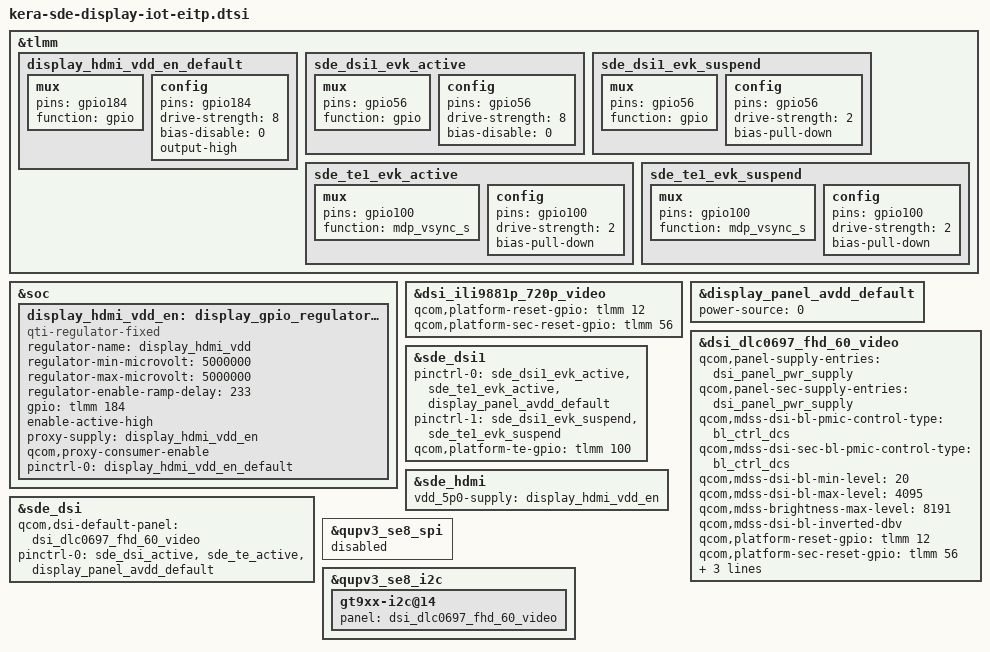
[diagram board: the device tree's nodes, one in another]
// SPDX-License-Identifier: BSD-3-Clause
/*
 * Copyright (c) Qualcomm Technologies, Inc. and/or its subsidiaries.
 */

#include "kera-sde-display-iot-cdp.dtsi"

&tlmm {
	display_hdmi_vdd_en_default: display_hdmi_vdd_en_default {
		mux {
			pins = "gpio184";
			function = "gpio";
		};

		config {
			pins = "gpio184";
			drive-strength = <8>;
			bias-disable = <0>;
			output-high;
		};
	};

	sde_dsi1_evk_active: sde_dsi1_evk_active {
		mux {
			pins = "gpio56";
			function = "gpio";
		};

		config {
			pins = "gpio56";
			drive-strength = <8>;   /* 8 mA */
			bias-disable = <0>;   /* no pull */
		};
	};

	sde_dsi1_evk_suspend: sde_dsi1_evk_suspend {
		mux {
			pins = "gpio56";
			function = "gpio";
		};

		config {
			pins = "gpio56";
			drive-strength = <2>;   /* 2 mA */
			bias-pull-down;         /* PULL DOWN */
		};
	};

	sde_te1_evk_active: sde_te1_evk_active {
		mux {
			pins = "gpio100";
			function = "mdp_vsync_s";
		};

		config {
			pins = "gpio100";
			drive-strength = <2>;   /* 2 mA */
			bias-pull-down;         /* PULL DOWN */
		};
	};

	sde_te1_evk_suspend: sde_te1_evk_suspend {
		mux {
			pins = "gpio100";
			function = "mdp_vsync_s";
		};

		config {
			pins = "gpio100";
			drive-strength = <2>;   /* 2 mA */
			bias-pull-down;         /* PULL DOWN */
		};
	};
};

&soc {
	display_hdmi_vdd_en: display_gpio_regulator@2 {
		compatible = "qti-regulator-fixed";
		regulator-name = "display_hdmi_vdd";
		regulator-min-microvolt = <5000000>;
		regulator-max-microvolt = <5000000>;
		regulator-enable-ramp-delay = <233>;
		gpio = <&tlmm 184 0>;
		enable-active-high;
		proxy-supply = <&display_hdmi_vdd_en>;
		qcom,proxy-consumer-enable;
		pinctrl-names = "default";
		pinctrl-0 = <&display_hdmi_vdd_en_default>;
	};
};

&dsi_ili9881p_720p_video {
	qcom,platform-reset-gpio = <&tlmm 12 0>;
	qcom,platform-sec-reset-gpio = <&tlmm 56 0>;
};

&display_panel_avdd_default {
	power-source = <0>;  /* 1.8V */
};

&dsi_dlc0697_fhd_60_video {
	qcom,panel-supply-entries = <&dsi_panel_pwr_supply>;
	qcom,panel-sec-supply-entries = <&dsi_panel_pwr_supply>;
	qcom,mdss-dsi-bl-pmic-control-type = "bl_ctrl_dcs";
	qcom,mdss-dsi-sec-bl-pmic-control-type = "bl_ctrl_dcs";
	qcom,mdss-dsi-bl-min-level = <20>;
	qcom,mdss-dsi-bl-max-level = <4095>;
	qcom,mdss-brightness-max-level = <8191>;
	qcom,mdss-dsi-bl-inverted-dbv;
	qcom,platform-reset-gpio = <&tlmm 12 0>;
	qcom,platform-sec-reset-gpio = <&tlmm 56 0>;
	qcom,platform-bklight-en-gpio = <&pmxr2230_gpios 2 0>;
	qcom,platform-en-gpio = <&pm8550vs_g_gpios 5 0>;
};


&sde_dsi {
	qcom,dsi-default-panel = <&dsi_dlc0697_fhd_60_video>;
	pinctrl-0 = <&sde_dsi_active &sde_te_active
				&display_panel_avdd_default>;
};

&sde_dsi1 {
	pinctrl-0 = <&sde_dsi1_evk_active &sde_te1_evk_active
				&display_panel_avdd_default>;
	pinctrl-1 = <&sde_dsi1_evk_suspend &sde_te1_evk_suspend>;
	qcom,platform-te-gpio = <&tlmm 100 0>;
};

&sde_hdmi {
	vdd_5p0-supply = <&display_hdmi_vdd_en>;
};

&qupv3_se8_spi {
	status = "disabled";
};

&qupv3_se8_i2c {
	status = "okay";

	gt9xx-i2c@14 {
		panel = <&dsi_dlc0697_fhd_60_video>;
	};
};
